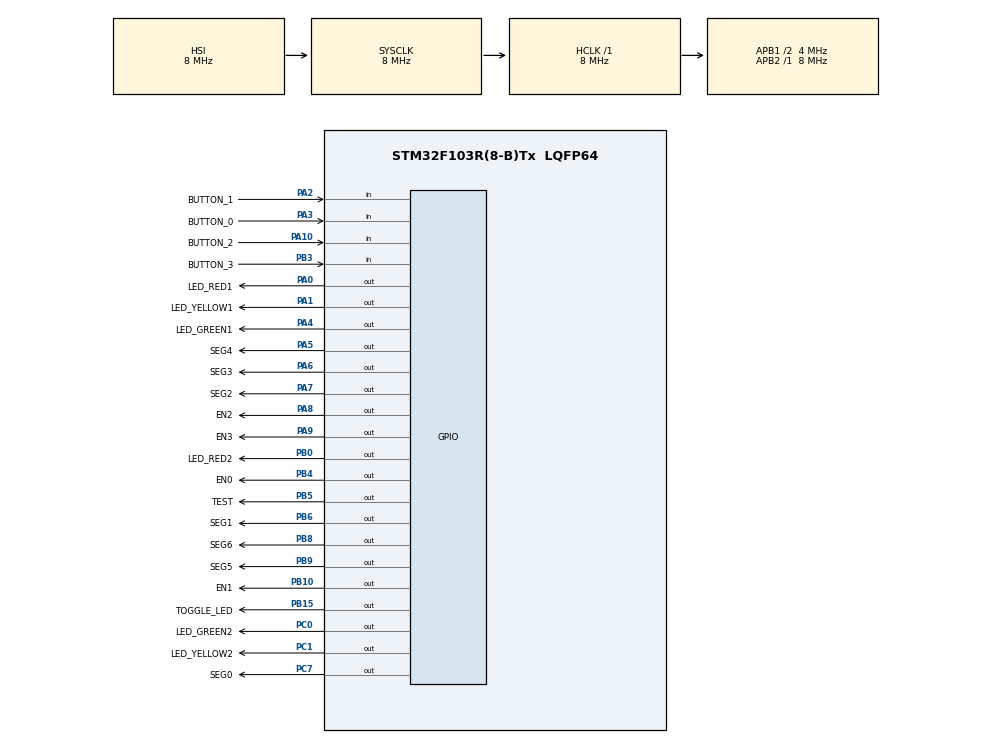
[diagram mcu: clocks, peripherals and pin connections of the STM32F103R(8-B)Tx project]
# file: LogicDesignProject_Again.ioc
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Mcu.Family=STM32F1
Mcu.Name=STM32F103R(8-B)Tx
Mcu.Package=LQFP64
NVIC.PriorityGroup=NVIC_PRIORITYGROUP_4
NVIC.TIM2_IRQn=true\:0\:0\:false\:false\:true\:true\:true\:true
PA0-WKUP.GPIO_Label=LED_RED1
PA0-WKUP.Signal=GPIO_Output
PA1.GPIO_Label=LED_YELLOW1
PA1.Signal=GPIO_Output
PA10.GPIO_Label=BUTTON_2
PA10.GPIO_PuPd=GPIO_PULLUP
PA10.Signal=GPIO_Input
PA13.Mode=Serial_Wire
PA13.Signal=SYS_JTMS-SWDIO
PA14.Mode=Serial_Wire
PA14.Signal=SYS_JTCK-SWCLK
PA2.GPIO_Label=BUTTON_1
PA2.GPIO_PuPd=GPIO_PULLUP
PA2.Signal=GPIO_Input
PA3.GPIO_Label=BUTTON_0
PA3.GPIO_PuPd=GPIO_PULLUP
PA3.Signal=GPIO_Input
PA4.GPIO_Label=LED_GREEN1
PA4.Signal=GPIO_Output
PA5.GPIO_Label=SEG4
PA5.Signal=GPIO_Output
PA6.GPIO_Label=SEG3
PA6.Signal=GPIO_Output
PA7.GPIO_Label=SEG2
PA7.Signal=GPIO_Output
PA8.GPIO_Label=EN2
PA8.Signal=GPIO_Output
PA9.GPIO_Label=EN3
PA9.Signal=GPIO_Output
PB0.GPIO_Label=LED_RED2
PB0.Signal=GPIO_Output
PB10.GPIO_Label=EN1
PB10.Signal=GPIO_Output
PB15.GPIO_Label=TOGGLE_LED
PB15.Signal=GPIO_Output
PB3.GPIO_Label=BUTTON_3
PB3.GPIO_PuPd=GPIO_PULLUP
PB3.Signal=GPIO_Input
PB4.GPIO_Label=EN0
PB4.Signal=GPIO_Output
PB5.GPIO_Label=TEST
PB5.Signal=GPIO_Output
PB6.GPIO_Label=SEG1
PB6.Signal=GPIO_Output
PB8.GPIO_Label=SEG6
PB8.Signal=GPIO_Output
PB9.GPIO_Label=SEG5
PB9.Signal=GPIO_Output
PC0.GPIO_Label=LED_GREEN2
PC0.Signal=GPIO_Output
PC1.GPIO_Label=LED_YELLOW2
PC1.Signal=GPIO_Output
PC7.GPIO_Label=SEG0
PC7.Signal=GPIO_Output
ProjectManager.HeapSize=0x200
ProjectManager.StackSize=0x400
ProjectManager.TargetToolchain=STM32CubeIDE
RCC.AHBFreq_Value=8000000
RCC.APB1CLKDivider=RCC_HCLK_DIV2
RCC.APB1Freq_Value=4000000
RCC.APB1TimFreq_Value=8000000
RCC.APB2Freq_Value=8000000
RCC.APB2TimFreq_Value=8000000
RCC.HCLKFreq_Value=8000000
RCC.PLLMUL=RCC_PLL_MUL16
RCC.RTCClockSelection=RCC_RTCCLKSOURCE_LSE
RCC.SYSCLKFreq_VALUE=8000000
RCC.USBFreq_Value=64000000
TIM2.Period=9
TIM2.Prescaler=799
VP_TIM2_VS_ClockSourceINT.Mode=Internal
board=NUCLEO-F103RB

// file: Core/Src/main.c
/* USER CODE BEGIN Header */
/**
  ******************************************************************************
  * @file           : main.c
  * @brief          : Main program body
  ******************************************************************************
  * @attention
  *
  * Copyright (c) 2023 STMicroelectronics.
  * All rights reserved.
  *
  * This software is licensed under terms that can be found in the LICENSE file
  * in the root directory of this software component.
  * If no LICENSE file comes with this software, it is provided AS-IS.
  *
  ******************************************************************************
  */
/* USER CODE END Header */
#include "main.h"

/* USER CODE BEGIN Includes */
#include "global.h"
/* USER CODE END Includes */

TIM_HandleTypeDef htim2;

void SystemClock_Config(void);
static void MX_GPIO_Init(void);
static void MX_TIM2_Init(void);

int main(void)
{

  /* MCU Configuration--------------------------------------------------------*/

  /* Reset of all peripherals, Initializes the Flash interface and the Systick. */
  HAL_Init();

  /* Configure the system clock */
  SystemClock_Config();

  /* Initialize all configured peripherals */
  MX_GPIO_Init();
  MX_TIM2_Init();
  /* USER CODE BEGIN 2 */
  HAL_TIM_Base_Start_IT (& htim2 );
  /* USER CODE END 2 */

  /* Infinite loop */
  /* USER CODE BEGIN WHILE */
  InitTimerSet();
  while (1)
  {
	  fsm_for_input_processing();

    /* USER CODE END WHILE */

  }
}

void SystemClock_Config(void)
{
  RCC_OscInitTypeDef RCC_OscInitStruct = {0};
  RCC_ClkInitTypeDef RCC_ClkInitStruct = {0};

  /** Initializes the RCC Oscillators according to the specified parameters
  * in the RCC_OscInitTypeDef structure.
  */
  RCC_OscInitStruct.OscillatorType = RCC_OSCILLATORTYPE_HSI;
  RCC_OscInitStruct.HSIState = RCC_HSI_ON;
  RCC_OscInitStruct.HSICalibrationValue = RCC_HSICALIBRATION_DEFAULT;
  RCC_OscInitStruct.PLL.PLLState = RCC_PLL_NONE;
  if (HAL_RCC_OscConfig(&RCC_OscInitStruct) != HAL_OK)
  {
    Error_Handler();
  }

  /** Initializes the CPU, AHB and APB buses clocks
  */
  RCC_ClkInitStruct.ClockType = RCC_CLOCKTYPE_HCLK|RCC_CLOCKTYPE_SYSCLK
                              |RCC_CLOCKTYPE_PCLK1|RCC_CLOCKTYPE_PCLK2;
  RCC_ClkInitStruct.SYSCLKSource = RCC_SYSCLKSOURCE_HSI;
  RCC_ClkInitStruct.AHBCLKDivider = RCC_SYSCLK_DIV1;
  RCC_ClkInitStruct.APB1CLKDivider = RCC_HCLK_DIV2;
  RCC_ClkInitStruct.APB2CLKDivider = RCC_HCLK_DIV1;

  if (HAL_RCC_ClockConfig(&RCC_ClkInitStruct, FLASH_LATENCY_0) != HAL_OK)
  {
    Error_Handler();
  }
}

static void MX_TIM2_Init(void)
{

  TIM_ClockConfigTypeDef sClockSourceConfig = {0};
  TIM_MasterConfigTypeDef sMasterConfig = {0};

  htim2.Instance = TIM2;
  htim2.Init.Prescaler = 799;
  htim2.Init.CounterMode = TIM_COUNTERMODE_UP;
  htim2.Init.Period = 9;
  htim2.Init.ClockDivision = TIM_CLOCKDIVISION_DIV1;
  htim2.Init.AutoReloadPreload = TIM_AUTORELOAD_PRELOAD_DISABLE;
  if (HAL_TIM_Base_Init(&htim2) != HAL_OK)
  {
    Error_Handler();
  }
  sClockSourceConfig.ClockSource = TIM_CLOCKSOURCE_INTERNAL;
  if (HAL_TIM_ConfigClockSource(&htim2, &sClockSourceConfig) != HAL_OK)
  {
    Error_Handler();
  }
  sMasterConfig.MasterOutputTrigger = TIM_TRGO_RESET;
  sMasterConfig.MasterSlaveMode = TIM_MASTERSLAVEMODE_DISABLE;
  if (HAL_TIMEx_MasterConfigSynchronization(&htim2, &sMasterConfig) != HAL_OK)
  {
    Error_Handler();
  }

}

static void MX_GPIO_Init(void)
{
  GPIO_InitTypeDef GPIO_InitStruct = {0};

  /* GPIO Ports Clock Enable */
  __HAL_RCC_GPIOC_CLK_ENABLE();
  __HAL_RCC_GPIOA_CLK_ENABLE();
  __HAL_RCC_GPIOB_CLK_ENABLE();

  /*Configure GPIO pin Output Level */
  HAL_GPIO_WritePin(GPIOC, LED_GREEN2_Pin|LED_YELLOW2_Pin|SEG0_Pin, GPIO_PIN_RESET);

  /*Configure GPIO pin Output Level */
  HAL_GPIO_WritePin(GPIOA, LED_RED1_Pin|LED_YELLOW1_Pin|LED_GREEN1_Pin|SEG4_Pin
                          |SEG3_Pin|SEG2_Pin|EN2_Pin|EN3_Pin, GPIO_PIN_RESET);

  /*Configure GPIO pin Output Level */
  HAL_GPIO_WritePin(GPIOB, LED_RED2_Pin|EN1_Pin|TOGGLE_LED_Pin|EN0_Pin
                          |TEST_Pin|SEG1_Pin|SEG6_Pin|SEG5_Pin, GPIO_PIN_RESET);

  /*Configure GPIO pins : LED_GREEN2_Pin LED_YELLOW2_Pin SEG0_Pin */
  GPIO_InitStruct.Pin = LED_GREEN2_Pin|LED_YELLOW2_Pin|SEG0_Pin;
  GPIO_InitStruct.Mode = GPIO_MODE_OUTPUT_PP;
  GPIO_InitStruct.Pull = GPIO_NOPULL;
  GPIO_InitStruct.Speed = GPIO_SPEED_FREQ_LOW;
  HAL_GPIO_Init(GPIOC, &GPIO_InitStruct);

  /*Configure GPIO pins : LED_RED1_Pin LED_YELLOW1_Pin LED_GREEN1_Pin SEG4_Pin
                           SEG3_Pin SEG2_Pin EN2_Pin EN3_Pin */
  GPIO_InitStruct.Pin = LED_RED1_Pin|LED_YELLOW1_Pin|LED_GREEN1_Pin|SEG4_Pin
                          |SEG3_Pin|SEG2_Pin|EN2_Pin|EN3_Pin;
  GPIO_InitStruct.Mode = GPIO_MODE_OUTPUT_PP;
  GPIO_InitStruct.Pull = GPIO_NOPULL;
  GPIO_InitStruct.Speed = GPIO_SPEED_FREQ_LOW;
  HAL_GPIO_Init(GPIOA, &GPIO_InitStruct);

  /*Configure GPIO pins : BUTTON_1_Pin BUTTON_0_Pin BUTTON_2_Pin */
  GPIO_InitStruct.Pin = BUTTON_1_Pin|BUTTON_0_Pin|BUTTON_2_Pin;
  GPIO_InitStruct.Mode = GPIO_MODE_INPUT;
  GPIO_InitStruct.Pull = GPIO_PULLUP;
  HAL_GPIO_Init(GPIOA, &GPIO_InitStruct);

  /*Configure GPIO pins : LED_RED2_Pin EN1_Pin TOGGLE_LED_Pin EN0_Pin
                           TEST_Pin SEG1_Pin SEG6_Pin SEG5_Pin */
  GPIO_InitStruct.Pin = LED_RED2_Pin|EN1_Pin|TOGGLE_LED_Pin|EN0_Pin
                          |TEST_Pin|SEG1_Pin|SEG6_Pin|SEG5_Pin;
  GPIO_InitStruct.Mode = GPIO_MODE_OUTPUT_PP;
  GPIO_InitStruct.Pull = GPIO_NOPULL;
  GPIO_InitStruct.Speed = GPIO_SPEED_FREQ_LOW;
  HAL_GPIO_Init(GPIOB, &GPIO_InitStruct);

  /*Configure GPIO pin : BUTTON_3_Pin */
  GPIO_InitStruct.Pin = BUTTON_3_Pin;
  GPIO_InitStruct.Mode = GPIO_MODE_INPUT;
  GPIO_InitStruct.Pull = GPIO_PULLUP;
  HAL_GPIO_Init(BUTTON_3_GPIO_Port, &GPIO_InitStruct);

}

void Error_Handler(void)
{
  __disable_irq();
  while (1)
  {
  }
}
